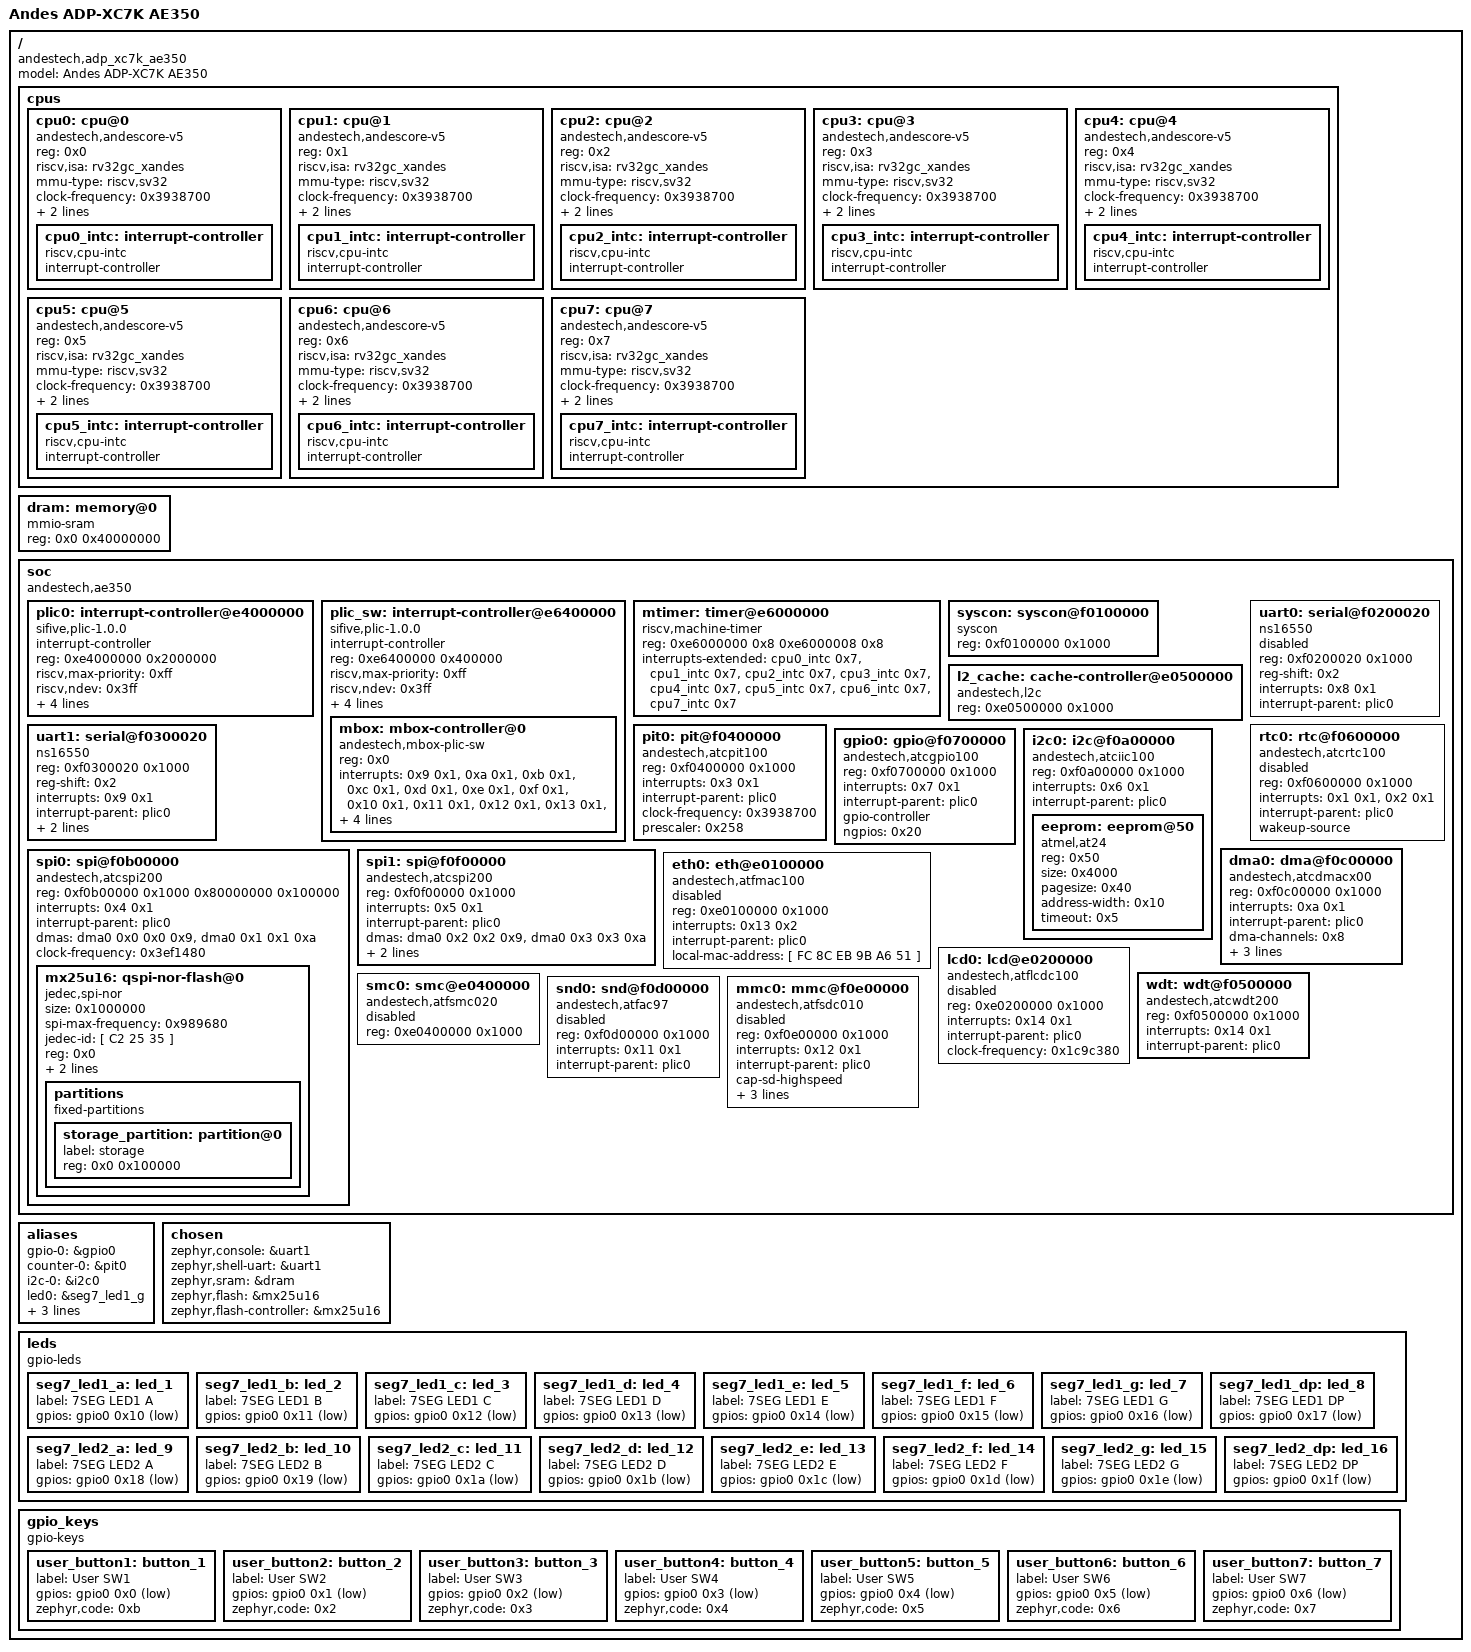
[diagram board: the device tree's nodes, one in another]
/dts-v1/;

/* node '/' defined in zephyr/dts/riscv/andes/andes_v5_ae350.dtsi:11 */
/ {
	#address-cells = < 0x1 >;                /* in zephyr/dts/riscv/andes/andes_v5_ae350.dtsi:12 */
	#size-cells = < 0x1 >;                   /* in zephyr/dts/riscv/andes/andes_v5_ae350.dtsi:13 */
	model = "Andes ADP-XC7K AE350";          /* in zephyr/boards/andestech/adp_xc7k_ae350/adp_xc7k_ae350.dts:14 */
	compatible = "andestech,adp_xc7k_ae350"; /* in zephyr/boards/andestech/adp_xc7k_ae350/adp_xc7k_ae350.dts:15 */

	/* node '/cpus' defined in zephyr/dts/riscv/andes/andes_v5_ae350.dtsi:15 */
	cpus {
		#address-cells = < 0x1 >; /* in zephyr/dts/riscv/andes/andes_v5_ae350.dtsi:16 */
		#size-cells = < 0x0 >;    /* in zephyr/dts/riscv/andes/andes_v5_ae350.dtsi:17 */

		/* node '/cpus/cpu@0' defined in zephyr/dts/riscv/andes/andes_v5_ae350.dtsi:19 */
		cpu0: cpu@0 {
			compatible = "andestech,andescore-v5",
			             "riscv";                  /* in zephyr/dts/riscv/andes/andes_v5_ae350.dtsi:20 */
			device_type = "cpu";                   /* in zephyr/dts/riscv/andes/andes_v5_ae350.dtsi:21 */
			reg = < 0x0 >;                         /* in zephyr/dts/riscv/andes/andes_v5_ae350.dtsi:22 */
			status = "okay";                       /* in zephyr/dts/riscv/andes/andes_v5_ae350.dtsi:23 */
			riscv,isa = "rv32gc_xandes";           /* in zephyr/dts/riscv/andes/andes_v5_ae350.dtsi:24 */
			mmu-type = "riscv,sv32";               /* in zephyr/dts/riscv/andes/andes_v5_ae350.dtsi:25 */
			clock-frequency = < 0x3938700 >;       /* in zephyr/dts/riscv/andes/andes_v5_ae350.dtsi:26 */
			i-cache-line-size = < 0x20 >;          /* in zephyr/dts/riscv/andes/andes_v5_ae350.dtsi:27 */
			d-cache-line-size = < 0x20 >;          /* in zephyr/dts/riscv/andes/andes_v5_ae350.dtsi:28 */

			/* node '/cpus/cpu@0/interrupt-controller' defined in zephyr/dts/riscv/andes/andes_v5_ae350.dtsi:30 */
			cpu0_intc: interrupt-controller {
				compatible = "riscv,cpu-intc"; /* in zephyr/dts/riscv/andes/andes_v5_ae350.dtsi:31 */
				#address-cells = < 0x0 >;      /* in zephyr/dts/riscv/andes/andes_v5_ae350.dtsi:32 */
				#interrupt-cells = < 0x1 >;    /* in zephyr/dts/riscv/andes/andes_v5_ae350.dtsi:33 */
				interrupt-controller;          /* in zephyr/dts/riscv/andes/andes_v5_ae350.dtsi:34 */
				phandle = < 0x1 >;             /* in zephyr/dts/riscv/andes/andes_v5_ae350.dtsi:192 */
			};
		};

		/* node '/cpus/cpu@1' defined in zephyr/dts/riscv/andes/andes_v5_ae350.dtsi:38 */
		cpu1: cpu@1 {
			compatible = "andestech,andescore-v5",
			             "riscv";                  /* in zephyr/dts/riscv/andes/andes_v5_ae350.dtsi:39 */
			device_type = "cpu";                   /* in zephyr/dts/riscv/andes/andes_v5_ae350.dtsi:40 */
			reg = < 0x1 >;                         /* in zephyr/dts/riscv/andes/andes_v5_ae350.dtsi:41 */
			status = "okay";                       /* in zephyr/dts/riscv/andes/andes_v5_ae350.dtsi:42 */
			riscv,isa = "rv32gc_xandes";           /* in zephyr/dts/riscv/andes/andes_v5_ae350.dtsi:43 */
			mmu-type = "riscv,sv32";               /* in zephyr/dts/riscv/andes/andes_v5_ae350.dtsi:44 */
			clock-frequency = < 0x3938700 >;       /* in zephyr/dts/riscv/andes/andes_v5_ae350.dtsi:45 */
			i-cache-line-size = < 0x20 >;          /* in zephyr/dts/riscv/andes/andes_v5_ae350.dtsi:46 */
			d-cache-line-size = < 0x20 >;          /* in zephyr/dts/riscv/andes/andes_v5_ae350.dtsi:47 */

			/* node '/cpus/cpu@1/interrupt-controller' defined in zephyr/dts/riscv/andes/andes_v5_ae350.dtsi:49 */
			cpu1_intc: interrupt-controller {
				compatible = "riscv,cpu-intc"; /* in zephyr/dts/riscv/andes/andes_v5_ae350.dtsi:50 */
				#address-cells = < 0x0 >;      /* in zephyr/dts/riscv/andes/andes_v5_ae350.dtsi:51 */
				#interrupt-cells = < 0x1 >;    /* in zephyr/dts/riscv/andes/andes_v5_ae350.dtsi:52 */
				interrupt-controller;          /* in zephyr/dts/riscv/andes/andes_v5_ae350.dtsi:53 */
				phandle = < 0x2 >;             /* in zephyr/dts/riscv/andes/andes_v5_ae350.dtsi:192 */
			};
		};

		/* node '/cpus/cpu@2' defined in zephyr/dts/riscv/andes/andes_v5_ae350.dtsi:57 */
		cpu2: cpu@2 {
			compatible = "andestech,andescore-v5",
			             "riscv";                  /* in zephyr/dts/riscv/andes/andes_v5_ae350.dtsi:58 */
			device_type = "cpu";                   /* in zephyr/dts/riscv/andes/andes_v5_ae350.dtsi:59 */
			reg = < 0x2 >;                         /* in zephyr/dts/riscv/andes/andes_v5_ae350.dtsi:60 */
			status = "okay";                       /* in zephyr/dts/riscv/andes/andes_v5_ae350.dtsi:61 */
			riscv,isa = "rv32gc_xandes";           /* in zephyr/dts/riscv/andes/andes_v5_ae350.dtsi:62 */
			mmu-type = "riscv,sv32";               /* in zephyr/dts/riscv/andes/andes_v5_ae350.dtsi:63 */
			clock-frequency = < 0x3938700 >;       /* in zephyr/dts/riscv/andes/andes_v5_ae350.dtsi:64 */
			i-cache-line-size = < 0x20 >;          /* in zephyr/dts/riscv/andes/andes_v5_ae350.dtsi:65 */
			d-cache-line-size = < 0x20 >;          /* in zephyr/dts/riscv/andes/andes_v5_ae350.dtsi:66 */

			/* node '/cpus/cpu@2/interrupt-controller' defined in zephyr/dts/riscv/andes/andes_v5_ae350.dtsi:68 */
			cpu2_intc: interrupt-controller {
				compatible = "riscv,cpu-intc"; /* in zephyr/dts/riscv/andes/andes_v5_ae350.dtsi:69 */
				#address-cells = < 0x0 >;      /* in zephyr/dts/riscv/andes/andes_v5_ae350.dtsi:70 */
				#interrupt-cells = < 0x1 >;    /* in zephyr/dts/riscv/andes/andes_v5_ae350.dtsi:71 */
				interrupt-controller;          /* in zephyr/dts/riscv/andes/andes_v5_ae350.dtsi:72 */
				phandle = < 0x3 >;             /* in zephyr/dts/riscv/andes/andes_v5_ae350.dtsi:192 */
			};
		};

		/* node '/cpus/cpu@3' defined in zephyr/dts/riscv/andes/andes_v5_ae350.dtsi:76 */
		cpu3: cpu@3 {
			compatible = "andestech,andescore-v5",
			             "riscv";                  /* in zephyr/dts/riscv/andes/andes_v5_ae350.dtsi:77 */
			device_type = "cpu";                   /* in zephyr/dts/riscv/andes/andes_v5_ae350.dtsi:78 */
			reg = < 0x3 >;                         /* in zephyr/dts/riscv/andes/andes_v5_ae350.dtsi:79 */
			status = "okay";                       /* in zephyr/dts/riscv/andes/andes_v5_ae350.dtsi:80 */
			riscv,isa = "rv32gc_xandes";           /* in zephyr/dts/riscv/andes/andes_v5_ae350.dtsi:81 */
			mmu-type = "riscv,sv32";               /* in zephyr/dts/riscv/andes/andes_v5_ae350.dtsi:82 */
			clock-frequency = < 0x3938700 >;       /* in zephyr/dts/riscv/andes/andes_v5_ae350.dtsi:83 */
			i-cache-line-size = < 0x20 >;          /* in zephyr/dts/riscv/andes/andes_v5_ae350.dtsi:84 */
			d-cache-line-size = < 0x20 >;          /* in zephyr/dts/riscv/andes/andes_v5_ae350.dtsi:85 */

			/* node '/cpus/cpu@3/interrupt-controller' defined in zephyr/dts/riscv/andes/andes_v5_ae350.dtsi:87 */
			cpu3_intc: interrupt-controller {
				compatible = "riscv,cpu-intc"; /* in zephyr/dts/riscv/andes/andes_v5_ae350.dtsi:88 */
				#address-cells = < 0x0 >;      /* in zephyr/dts/riscv/andes/andes_v5_ae350.dtsi:89 */
				#interrupt-cells = < 0x1 >;    /* in zephyr/dts/riscv/andes/andes_v5_ae350.dtsi:90 */
				interrupt-controller;          /* in zephyr/dts/riscv/andes/andes_v5_ae350.dtsi:91 */
				phandle = < 0x4 >;             /* in zephyr/dts/riscv/andes/andes_v5_ae350.dtsi:192 */
			};
		};

		/* node '/cpus/cpu@4' defined in zephyr/dts/riscv/andes/andes_v5_ae350.dtsi:95 */
		cpu4: cpu@4 {
			compatible = "andestech,andescore-v5",
			             "riscv";                  /* in zephyr/dts/riscv/andes/andes_v5_ae350.dtsi:96 */
			device_type = "cpu";                   /* in zephyr/dts/riscv/andes/andes_v5_ae350.dtsi:97 */
			reg = < 0x4 >;                         /* in zephyr/dts/riscv/andes/andes_v5_ae350.dtsi:98 */
			status = "okay";                       /* in zephyr/dts/riscv/andes/andes_v5_ae350.dtsi:99 */
			riscv,isa = "rv32gc_xandes";           /* in zephyr/dts/riscv/andes/andes_v5_ae350.dtsi:100 */
			mmu-type = "riscv,sv32";               /* in zephyr/dts/riscv/andes/andes_v5_ae350.dtsi:101 */
			clock-frequency = < 0x3938700 >;       /* in zephyr/dts/riscv/andes/andes_v5_ae350.dtsi:102 */
			i-cache-line-size = < 0x20 >;          /* in zephyr/dts/riscv/andes/andes_v5_ae350.dtsi:103 */
			d-cache-line-size = < 0x20 >;          /* in zephyr/dts/riscv/andes/andes_v5_ae350.dtsi:104 */

			/* node '/cpus/cpu@4/interrupt-controller' defined in zephyr/dts/riscv/andes/andes_v5_ae350.dtsi:106 */
			cpu4_intc: interrupt-controller {
				compatible = "riscv,cpu-intc"; /* in zephyr/dts/riscv/andes/andes_v5_ae350.dtsi:107 */
				#address-cells = < 0x0 >;      /* in zephyr/dts/riscv/andes/andes_v5_ae350.dtsi:108 */
				#interrupt-cells = < 0x1 >;    /* in zephyr/dts/riscv/andes/andes_v5_ae350.dtsi:109 */
				interrupt-controller;          /* in zephyr/dts/riscv/andes/andes_v5_ae350.dtsi:110 */
				phandle = < 0x5 >;             /* in zephyr/dts/riscv/andes/andes_v5_ae350.dtsi:192 */
			};
		};

		/* node '/cpus/cpu@5' defined in zephyr/dts/riscv/andes/andes_v5_ae350.dtsi:114 */
		cpu5: cpu@5 {
			compatible = "andestech,andescore-v5",
			             "riscv";                  /* in zephyr/dts/riscv/andes/andes_v5_ae350.dtsi:115 */
			device_type = "cpu";                   /* in zephyr/dts/riscv/andes/andes_v5_ae350.dtsi:116 */
			reg = < 0x5 >;                         /* in zephyr/dts/riscv/andes/andes_v5_ae350.dtsi:117 */
			status = "okay";                       /* in zephyr/dts/riscv/andes/andes_v5_ae350.dtsi:118 */
			riscv,isa = "rv32gc_xandes";           /* in zephyr/dts/riscv/andes/andes_v5_ae350.dtsi:119 */
			mmu-type = "riscv,sv32";               /* in zephyr/dts/riscv/andes/andes_v5_ae350.dtsi:120 */
			clock-frequency = < 0x3938700 >;       /* in zephyr/dts/riscv/andes/andes_v5_ae350.dtsi:121 */
			i-cache-line-size = < 0x20 >;          /* in zephyr/dts/riscv/andes/andes_v5_ae350.dtsi:122 */
			d-cache-line-size = < 0x20 >;          /* in zephyr/dts/riscv/andes/andes_v5_ae350.dtsi:123 */

			/* node '/cpus/cpu@5/interrupt-controller' defined in zephyr/dts/riscv/andes/andes_v5_ae350.dtsi:125 */
			cpu5_intc: interrupt-controller {
				compatible = "riscv,cpu-intc"; /* in zephyr/dts/riscv/andes/andes_v5_ae350.dtsi:126 */
				#address-cells = < 0x0 >;      /* in zephyr/dts/riscv/andes/andes_v5_ae350.dtsi:127 */
				#interrupt-cells = < 0x1 >;    /* in zephyr/dts/riscv/andes/andes_v5_ae350.dtsi:128 */
				interrupt-controller;          /* in zephyr/dts/riscv/andes/andes_v5_ae350.dtsi:129 */
				phandle = < 0x6 >;             /* in zephyr/dts/riscv/andes/andes_v5_ae350.dtsi:192 */
			};
		};

		/* node '/cpus/cpu@6' defined in zephyr/dts/riscv/andes/andes_v5_ae350.dtsi:133 */
		cpu6: cpu@6 {
			compatible = "andestech,andescore-v5",
			             "riscv";                  /* in zephyr/dts/riscv/andes/andes_v5_ae350.dtsi:134 */
			device_type = "cpu";                   /* in zephyr/dts/riscv/andes/andes_v5_ae350.dtsi:135 */
			reg = < 0x6 >;                         /* in zephyr/dts/riscv/andes/andes_v5_ae350.dtsi:136 */
			status = "okay";                       /* in zephyr/dts/riscv/andes/andes_v5_ae350.dtsi:137 */
			riscv,isa = "rv32gc_xandes";           /* in zephyr/dts/riscv/andes/andes_v5_ae350.dtsi:138 */
			mmu-type = "riscv,sv32";               /* in zephyr/dts/riscv/andes/andes_v5_ae350.dtsi:139 */
			clock-frequency = < 0x3938700 >;       /* in zephyr/dts/riscv/andes/andes_v5_ae350.dtsi:140 */
			i-cache-line-size = < 0x20 >;          /* in zephyr/dts/riscv/andes/andes_v5_ae350.dtsi:141 */
			d-cache-line-size = < 0x20 >;          /* in zephyr/dts/riscv/andes/andes_v5_ae350.dtsi:142 */

			/* node '/cpus/cpu@6/interrupt-controller' defined in zephyr/dts/riscv/andes/andes_v5_ae350.dtsi:144 */
			cpu6_intc: interrupt-controller {
				compatible = "riscv,cpu-intc"; /* in zephyr/dts/riscv/andes/andes_v5_ae350.dtsi:145 */
				#address-cells = < 0x0 >;      /* in zephyr/dts/riscv/andes/andes_v5_ae350.dtsi:146 */
				#interrupt-cells = < 0x1 >;    /* in zephyr/dts/riscv/andes/andes_v5_ae350.dtsi:147 */
				interrupt-controller;          /* in zephyr/dts/riscv/andes/andes_v5_ae350.dtsi:148 */
				phandle = < 0x7 >;             /* in zephyr/dts/riscv/andes/andes_v5_ae350.dtsi:192 */
			};
		};

		/* node '/cpus/cpu@7' defined in zephyr/dts/riscv/andes/andes_v5_ae350.dtsi:152 */
		cpu7: cpu@7 {
			compatible = "andestech,andescore-v5",
			             "riscv";                  /* in zephyr/dts/riscv/andes/andes_v5_ae350.dtsi:153 */
			device_type = "cpu";                   /* in zephyr/dts/riscv/andes/andes_v5_ae350.dtsi:154 */
			reg = < 0x7 >;                         /* in zephyr/dts/riscv/andes/andes_v5_ae350.dtsi:155 */
			status = "okay";                       /* in zephyr/dts/riscv/andes/andes_v5_ae350.dtsi:156 */
			riscv,isa = "rv32gc_xandes";           /* in zephyr/dts/riscv/andes/andes_v5_ae350.dtsi:157 */
			mmu-type = "riscv,sv32";               /* in zephyr/dts/riscv/andes/andes_v5_ae350.dtsi:158 */
			clock-frequency = < 0x3938700 >;       /* in zephyr/dts/riscv/andes/andes_v5_ae350.dtsi:159 */
			i-cache-line-size = < 0x20 >;          /* in zephyr/dts/riscv/andes/andes_v5_ae350.dtsi:160 */
			d-cache-line-size = < 0x20 >;          /* in zephyr/dts/riscv/andes/andes_v5_ae350.dtsi:161 */

			/* node '/cpus/cpu@7/interrupt-controller' defined in zephyr/dts/riscv/andes/andes_v5_ae350.dtsi:163 */
			cpu7_intc: interrupt-controller {
				compatible = "riscv,cpu-intc"; /* in zephyr/dts/riscv/andes/andes_v5_ae350.dtsi:164 */
				#address-cells = < 0x0 >;      /* in zephyr/dts/riscv/andes/andes_v5_ae350.dtsi:165 */
				#interrupt-cells = < 0x1 >;    /* in zephyr/dts/riscv/andes/andes_v5_ae350.dtsi:166 */
				interrupt-controller;          /* in zephyr/dts/riscv/andes/andes_v5_ae350.dtsi:167 */
				phandle = < 0x8 >;             /* in zephyr/dts/riscv/andes/andes_v5_ae350.dtsi:192 */
			};
		};
	};

	/* node '/memory@0' defined in zephyr/dts/riscv/andes/andes_v5_ae350.dtsi:172 */
	dram: memory@0 {
		device_type = "memory";   /* in zephyr/dts/riscv/andes/andes_v5_ae350.dtsi:173 */
		compatible = "mmio-sram"; /* in zephyr/dts/riscv/andes/andes_v5_ae350.dtsi:174 */
		reg = < 0x0 0x40000000 >; /* in zephyr/dts/riscv/andes/andes_v5_ae350.dtsi:175 */
	};

	/* node '/soc' defined in zephyr/dts/riscv/andes/andes_v5_ae350.dtsi:178 */
	soc {
		#address-cells = < 0x1 >;       /* in zephyr/dts/riscv/andes/andes_v5_ae350.dtsi:179 */
		#size-cells = < 0x1 >;          /* in zephyr/dts/riscv/andes/andes_v5_ae350.dtsi:180 */
		compatible = "andestech,ae350"; /* in zephyr/dts/riscv/andes/andes_v5_ae350.dtsi:181 */
		ranges;                         /* in zephyr/dts/riscv/andes/andes_v5_ae350.dtsi:182 */

		/* node '/soc/interrupt-controller@e4000000' defined in zephyr/dts/riscv/andes/andes_v5_ae350.dtsi:184 */
		plic0: interrupt-controller@e4000000 {
			compatible = "sifive,plic-1.0.0",
			             "andestech,nceplic100";                                                                          /* in zephyr/dts/riscv/andes/andes_v5_ae350.dtsi:185 */
			#address-cells = < 0x1 >;                                                                                     /* in zephyr/dts/riscv/andes/andes_v5_ae350.dtsi:186 */
			#interrupt-cells = < 0x2 >;                                                                                   /* in zephyr/dts/riscv/andes/andes_v5_ae350.dtsi:187 */
			interrupt-controller;                                                                                         /* in zephyr/dts/riscv/andes/andes_v5_ae350.dtsi:188 */
			reg = < 0xe4000000 0x2000000 >;                                                                               /* in zephyr/dts/riscv/andes/andes_v5_ae350.dtsi:189 */
			riscv,max-priority = < 0xff >;                                                                                /* in zephyr/dts/riscv/andes/andes_v5_ae350.dtsi:190 */
			riscv,ndev = < 0x3ff >;                                                                                       /* in zephyr/dts/riscv/andes/andes_v5_ae350.dtsi:191 */
			interrupts-extended = < &cpu0_intc 0xb &cpu1_intc 0xb &cpu2_intc 0xb &cpu3_intc 0xb &cpu4_intc 0xb &cpu5_intc
			                        0xb &cpu6_intc 0xb &cpu7_intc 0xb >;                                                  /* in zephyr/dts/riscv/andes/andes_v5_ae350.dtsi:192 */
			phandle = < 0xa >;                                                                                            /* in zephyr/dts/riscv/andes/andes_v5_ae350.dtsi:261 */
		};

		/* node '/soc/interrupt-controller@e6400000' defined in zephyr/dts/riscv/andes/andes_v5_ae350.dtsi:198 */
		plic_sw: interrupt-controller@e6400000 {
			compatible = "sifive,plic-1.0.0",
			             "andestech,nceplic100";                                                                          /* in zephyr/dts/riscv/andes/andes_v5_ae350.dtsi:199 */
			#address-cells = < 0x1 >;                                                                                     /* in zephyr/dts/riscv/andes/andes_v5_ae350.dtsi:200 */
			#interrupt-cells = < 0x2 >;                                                                                   /* in zephyr/dts/riscv/andes/andes_v5_ae350.dtsi:201 */
			interrupt-controller;                                                                                         /* in zephyr/dts/riscv/andes/andes_v5_ae350.dtsi:202 */
			reg = < 0xe6400000 0x400000 >;                                                                                /* in zephyr/dts/riscv/andes/andes_v5_ae350.dtsi:203 */
			riscv,max-priority = < 0xff >;                                                                                /* in zephyr/dts/riscv/andes/andes_v5_ae350.dtsi:204 */
			riscv,ndev = < 0x3ff >;                                                                                       /* in zephyr/dts/riscv/andes/andes_v5_ae350.dtsi:205 */
			interrupts-extended = < &cpu0_intc 0x3 &cpu1_intc 0x3 &cpu2_intc 0x3 &cpu3_intc 0x3 &cpu4_intc 0x3 &cpu5_intc
			                        0x3 &cpu6_intc 0x3 &cpu7_intc 0x3 >;                                                  /* in zephyr/dts/riscv/andes/andes_v5_ae350.dtsi:206 */
			#size-cells = < 0x0 >;                                                                                        /* in zephyr/dts/riscv/andes/andes_v5_ae350.dtsi:211 */
			phandle = < 0x9 >;                                                                                            /* in zephyr/dts/riscv/andes/andes_v5_ae350.dtsi:229 */

			/* node '/soc/interrupt-controller@e6400000/mbox-controller@0' defined in zephyr/dts/riscv/andes/andes_v5_ae350.dtsi:213 */
			mbox: mbox-controller@0 {
				compatible = "andestech,mbox-plic-sw"; /* in zephyr/dts/riscv/andes/andes_v5_ae350.dtsi:214 */
				#mbox-cells = < 0x1 >;                 /* in zephyr/dts/riscv/andes/andes_v5_ae350.dtsi:215 */
				reg = < 0x0 >;                         /* in zephyr/dts/riscv/andes/andes_v5_ae350.dtsi:216 */
				interrupts = < 0x9 0x1 >,
				             < 0xa 0x1 >,
				             < 0xb 0x1 >,
				             < 0xc 0x1 >,
				             < 0xd 0x1 >,
				             < 0xe 0x1 >,
				             < 0xf 0x1 >,
				             < 0x10 0x1 >,
				             < 0x11 0x1 >,
				             < 0x12 0x1 >,
				             < 0x13 0x1 >,
				             < 0x14 0x1 >,
				             < 0x15 0x1 >,
				             < 0x16 0x1 >,
				             < 0x17 0x1 >,
				             < 0x18 0x1 >,
				             < 0x19 0x1 >,
				             < 0x1a 0x1 >,
				             < 0x1b 0x1 >,
				             < 0x1c 0x1 >,
				             < 0x1d 0x1 >,
				             < 0x1e 0x1 >,
				             < 0x1f 0x1 >;             /* in zephyr/dts/riscv/andes/andes_v5_ae350.dtsi:217 */
				interrupt-names = "mbox_9",
				                  "mbox_10",
				                  "mbox_11",
				                  "mbox_12",
				                  "mbox_13",
				                  "mbox_14",
				                  "mbox_15",
				                  "mbox_16",
				                  "mbox_17",
				                  "mbox_18",
				                  "mbox_19",
				                  "mbox_20",
				                  "mbox_21",
				                  "mbox_22",
				                  "mbox_23",
				                  "mbox_24",
				                  "mbox_25",
				                  "mbox_26",
				                  "mbox_27",
				                  "mbox_28",
				                  "mbox_29",
				                  "mbox_30",
				                  "mbox_31";           /* in zephyr/dts/riscv/andes/andes_v5_ae350.dtsi:223 */
				interrupt-parent = < &plic_sw >;       /* in zephyr/dts/riscv/andes/andes_v5_ae350.dtsi:229 */
				status = "okay";                       /* in zephyr/boards/andestech/adp_xc7k_ae350/adp_xc7k_ae350.dts:19 */
			};
		};

		/* node '/soc/timer@e6000000' defined in zephyr/dts/riscv/andes/andes_v5_ae350.dtsi:234 */
		mtimer: timer@e6000000 {
			compatible = "riscv,machine-timer";                                                                           /* in zephyr/dts/riscv/andes/andes_v5_ae350.dtsi:235 */
			reg = < 0xe6000000 0x8 0xe6000008 0x8 >;                                                                      /* in zephyr/dts/riscv/andes/andes_v5_ae350.dtsi:236 */
			reg-names = "mtime",
			            "mtimecmp";                                                                                       /* in zephyr/dts/riscv/andes/andes_v5_ae350.dtsi:237 */
			interrupts-extended = < &cpu0_intc 0x7 &cpu1_intc 0x7 &cpu2_intc 0x7 &cpu3_intc 0x7 &cpu4_intc 0x7 &cpu5_intc
			                        0x7 &cpu6_intc 0x7 &cpu7_intc 0x7 >;                                                  /* in zephyr/dts/riscv/andes/andes_v5_ae350.dtsi:238 */
		};

		/* node '/soc/syscon@f0100000' defined in zephyr/dts/riscv/andes/andes_v5_ae350.dtsi:244 */
		syscon: syscon@f0100000 {
			compatible = "syscon",
			             "andestech,atcsmu100"; /* in zephyr/dts/riscv/andes/andes_v5_ae350.dtsi:245 */
			reg = < 0xf0100000 0x1000 >;        /* in zephyr/dts/riscv/andes/andes_v5_ae350.dtsi:246 */
			status = "okay";                    /* in zephyr/boards/andestech/adp_xc7k_ae350/adp_xc7k_ae350_common.dtsi:164 */
		};

		/* node '/soc/cache-controller@e0500000' defined in zephyr/dts/riscv/andes/andes_v5_ae350.dtsi:250 */
		l2_cache: cache-controller@e0500000 {
			compatible = "andestech,l2c"; /* in zephyr/dts/riscv/andes/andes_v5_ae350.dtsi:251 */
			reg = < 0xe0500000 0x1000 >;  /* in zephyr/dts/riscv/andes/andes_v5_ae350.dtsi:252 */
			status = "okay";              /* in zephyr/boards/andestech/adp_xc7k_ae350/adp_xc7k_ae350_common.dtsi:160 */
		};

		/* node '/soc/serial@f0200020' defined in zephyr/dts/riscv/andes/andes_v5_ae350.dtsi:256 */
		uart0: serial@f0200020 {
			compatible = "ns16550";        /* in zephyr/dts/riscv/andes/andes_v5_ae350.dtsi:257 */
			reg = < 0xf0200020 0x1000 >;   /* in zephyr/dts/riscv/andes/andes_v5_ae350.dtsi:258 */
			reg-shift = < 0x2 >;           /* in zephyr/dts/riscv/andes/andes_v5_ae350.dtsi:259 */
			interrupts = < 0x8 0x1 >;      /* in zephyr/dts/riscv/andes/andes_v5_ae350.dtsi:260 */
			interrupt-parent = < &plic0 >; /* in zephyr/dts/riscv/andes/andes_v5_ae350.dtsi:261 */
			status = "disabled";           /* in zephyr/dts/riscv/andes/andes_v5_ae350.dtsi:262 */
		};

		/* node '/soc/serial@f0300020' defined in zephyr/dts/riscv/andes/andes_v5_ae350.dtsi:265 */
		uart1: serial@f0300020 {
			compatible = "ns16550";          /* in zephyr/dts/riscv/andes/andes_v5_ae350.dtsi:266 */
			reg = < 0xf0300020 0x1000 >;     /* in zephyr/dts/riscv/andes/andes_v5_ae350.dtsi:267 */
			reg-shift = < 0x2 >;             /* in zephyr/dts/riscv/andes/andes_v5_ae350.dtsi:268 */
			interrupts = < 0x9 0x1 >;        /* in zephyr/dts/riscv/andes/andes_v5_ae350.dtsi:269 */
			interrupt-parent = < &plic0 >;   /* in zephyr/dts/riscv/andes/andes_v5_ae350.dtsi:270 */
			status = "okay";                 /* in zephyr/boards/andestech/adp_xc7k_ae350/adp_xc7k_ae350_common.dtsi:168 */
			clock-frequency = < 0x1312d00 >; /* in zephyr/boards/andestech/adp_xc7k_ae350/adp_xc7k_ae350_common.dtsi:169 */
			current-speed = < 0x1c200 >;     /* in zephyr/boards/andestech/adp_xc7k_ae350/adp_xc7k_ae350_common.dtsi:170 */
		};

		/* node '/soc/pit@f0400000' defined in zephyr/dts/riscv/andes/andes_v5_ae350.dtsi:274 */
		pit0: pit@f0400000 {
			compatible = "andestech,atcpit100"; /* in zephyr/dts/riscv/andes/andes_v5_ae350.dtsi:275 */
			reg = < 0xf0400000 0x1000 >;        /* in zephyr/dts/riscv/andes/andes_v5_ae350.dtsi:276 */
			interrupts = < 0x3 0x1 >;           /* in zephyr/dts/riscv/andes/andes_v5_ae350.dtsi:277 */
			interrupt-parent = < &plic0 >;      /* in zephyr/dts/riscv/andes/andes_v5_ae350.dtsi:278 */
			clock-frequency = < 0x3938700 >;    /* in zephyr/dts/riscv/andes/andes_v5_ae350.dtsi:279 */
			prescaler = < 0x258 >;              /* in zephyr/dts/riscv/andes/andes_v5_ae350.dtsi:280 */
			status = "okay";                    /* in zephyr/boards/andestech/adp_xc7k_ae350/adp_xc7k_ae350_common.dtsi:178 */
		};

		/* node '/soc/rtc@f0600000' defined in zephyr/dts/riscv/andes/andes_v5_ae350.dtsi:284 */
		rtc0: rtc@f0600000 {
			compatible = "andestech,atcrtc100"; /* in zephyr/dts/riscv/andes/andes_v5_ae350.dtsi:285 */
			reg = < 0xf0600000 0x1000 >;        /* in zephyr/dts/riscv/andes/andes_v5_ae350.dtsi:286 */
			interrupts = < 0x1 0x1 >,
			             < 0x2 0x1 >;           /* in zephyr/dts/riscv/andes/andes_v5_ae350.dtsi:287 */
			interrupt-parent = < &plic0 >;      /* in zephyr/dts/riscv/andes/andes_v5_ae350.dtsi:288 */
			wakeup-source;                      /* in zephyr/dts/riscv/andes/andes_v5_ae350.dtsi:289 */
			status = "disabled";                /* in zephyr/dts/riscv/andes/andes_v5_ae350.dtsi:290 */
		};

		/* node '/soc/gpio@f0700000' defined in zephyr/dts/riscv/andes/andes_v5_ae350.dtsi:293 */
		gpio0: gpio@f0700000 {
			compatible = "andestech,atcgpio100"; /* in zephyr/dts/riscv/andes/andes_v5_ae350.dtsi:294 */
			reg = < 0xf0700000 0x1000 >;         /* in zephyr/dts/riscv/andes/andes_v5_ae350.dtsi:295 */
			interrupts = < 0x7 0x1 >;            /* in zephyr/dts/riscv/andes/andes_v5_ae350.dtsi:296 */
			interrupt-parent = < &plic0 >;       /* in zephyr/dts/riscv/andes/andes_v5_ae350.dtsi:297 */
			gpio-controller;                     /* in zephyr/dts/riscv/andes/andes_v5_ae350.dtsi:298 */
			ngpios = < 0x20 >;                   /* in zephyr/dts/riscv/andes/andes_v5_ae350.dtsi:299 */
			#gpio-cells = < 0x2 >;               /* in zephyr/dts/riscv/andes/andes_v5_ae350.dtsi:300 */
			status = "okay";                     /* in zephyr/boards/andestech/adp_xc7k_ae350/adp_xc7k_ae350_common.dtsi:174 */
			phandle = < 0xc >;                   /* in zephyr/boards/andestech/adp_xc7k_ae350/adp_xc7k_ae350_common.dtsi:224 */
		};

		/* node '/soc/i2c@f0a00000' defined in zephyr/dts/riscv/andes/andes_v5_ae350.dtsi:304 */
		i2c0: i2c@f0a00000 {
			compatible = "andestech,atciic100"; /* in zephyr/dts/riscv/andes/andes_v5_ae350.dtsi:305 */
			reg = < 0xf0a00000 0x1000 >;        /* in zephyr/dts/riscv/andes/andes_v5_ae350.dtsi:306 */
			interrupts = < 0x6 0x1 >;           /* in zephyr/dts/riscv/andes/andes_v5_ae350.dtsi:307 */
			interrupt-parent = < &plic0 >;      /* in zephyr/dts/riscv/andes/andes_v5_ae350.dtsi:308 */
			#address-cells = < 0x1 >;           /* in zephyr/dts/riscv/andes/andes_v5_ae350.dtsi:309 */
			#size-cells = < 0x0 >;              /* in zephyr/dts/riscv/andes/andes_v5_ae350.dtsi:310 */
			status = "okay";                    /* in zephyr/boards/andestech/adp_xc7k_ae350/adp_xc7k_ae350_common.dtsi:209 */

			/* node '/soc/i2c@f0a00000/eeprom@50' defined in zephyr/boards/andestech/adp_xc7k_ae350/adp_xc7k_ae350_common.dtsi:211 */
			eeprom: eeprom@50 {
				compatible = "atmel,at24"; /* in zephyr/boards/andestech/adp_xc7k_ae350/adp_xc7k_ae350_common.dtsi:212 */
				reg = < 0x50 >;            /* in zephyr/boards/andestech/adp_xc7k_ae350/adp_xc7k_ae350_common.dtsi:213 */
				status = "okay";           /* in zephyr/boards/andestech/adp_xc7k_ae350/adp_xc7k_ae350_common.dtsi:214 */
				size = < 0x4000 >;         /* in zephyr/boards/andestech/adp_xc7k_ae350/adp_xc7k_ae350_common.dtsi:215 */
				pagesize = < 0x40 >;       /* in zephyr/boards/andestech/adp_xc7k_ae350/adp_xc7k_ae350_common.dtsi:216 */
				address-width = < 0x10 >;  /* in zephyr/boards/andestech/adp_xc7k_ae350/adp_xc7k_ae350_common.dtsi:217 */
				timeout = < 0x5 >;         /* in zephyr/boards/andestech/adp_xc7k_ae350/adp_xc7k_ae350_common.dtsi:218 */
			};
		};

		/* node '/soc/spi@f0b00000' defined in zephyr/dts/riscv/andes/andes_v5_ae350.dtsi:314 */
		spi0: spi@f0b00000 {
			compatible = "andestech,atcspi200";              /* in zephyr/dts/riscv/andes/andes_v5_ae350.dtsi:315 */
			reg = < 0xf0b00000 0x1000 0x80000000 0x100000 >; /* in zephyr/dts/riscv/andes/andes_v5_ae350.dtsi:316 */
			reg-names = "control",
			            "mem";                               /* in zephyr/dts/riscv/andes/andes_v5_ae350.dtsi:318 */
			interrupts = < 0x4 0x1 >;                        /* in zephyr/dts/riscv/andes/andes_v5_ae350.dtsi:319 */
			interrupt-parent = < &plic0 >;                   /* in zephyr/dts/riscv/andes/andes_v5_ae350.dtsi:320 */
			dmas = < &dma0 0x0 0x0 0x9 >,
			       < &dma0 0x1 0x1 0xa >;                    /* in zephyr/dts/riscv/andes/andes_v5_ae350.dtsi:321 */
			dma-names = "tx",
			            "rx";                                /* in zephyr/dts/riscv/andes/andes_v5_ae350.dtsi:323 */
			#address-cells = < 0x1 >;                        /* in zephyr/dts/riscv/andes/andes_v5_ae350.dtsi:324 */
			#size-cells = < 0x0 >;                           /* in zephyr/dts/riscv/andes/andes_v5_ae350.dtsi:325 */
			clock-frequency = < 0x3ef1480 >;                 /* in zephyr/dts/riscv/andes/andes_v5_ae350.dtsi:326 */
			status = "okay";                                 /* in zephyr/boards/andestech/adp_xc7k_ae350/adp_xc7k_ae350_common.dtsi:182 */

			/* node '/soc/spi@f0b00000/qspi-nor-flash@0' defined in zephyr/boards/andestech/adp_xc7k_ae350/adp_xc7k_ae350_common.dtsi:184 */
			mx25u16: qspi-nor-flash@0 {
				compatible = "jedec,spi-nor",
				             "andestech,qspi-nor";                                                            /* in zephyr/boards/andestech/adp_xc7k_ae350/adp_xc7k_ae350_common.dtsi:185 */
				size = < 0x1000000 >;                                                                         /* in zephyr/boards/andestech/adp_xc7k_ae350/adp_xc7k_ae350_common.dtsi:186 */
				spi-max-frequency = < 0x989680 >;                                                             /* in zephyr/boards/andestech/adp_xc7k_ae350/adp_xc7k_ae350_common.dtsi:187 */
				jedec-id = [ C2 25 35 ];                                                                      /* in zephyr/boards/andestech/adp_xc7k_ae350/adp_xc7k_ae350_common.dtsi:188 */
				status = "okay";                                                                              /* in zephyr/boards/andestech/adp_xc7k_ae350/adp_xc7k_ae350_common.dtsi:189 */
				reg = < 0x0 >;                                                                                /* in zephyr/boards/andestech/adp_xc7k_ae350/adp_xc7k_ae350_common.dtsi:190 */
				sfdp-bfp = [ E5 20 F1 FF FF FF FF 00 44 EB 08 6B 08 3B 04 BB FE FF FF FF FF FF 00 FF FF FF 44
				             EB 0C 20 0F 52 10 D8 00 FF ];                                                    /* in zephyr/boards/andestech/adp_xc7k_ae350/adp_xc7k_ae350_common.dtsi:191 */

				/* node '/soc/spi@f0b00000/qspi-nor-flash@0/partitions' defined in zephyr/boards/andestech/adp_xc7k_ae350/adp_xc7k_ae350_common.dtsi:195 */
				partitions {
					compatible = "fixed-partitions"; /* in zephyr/boards/andestech/adp_xc7k_ae350/adp_xc7k_ae350_common.dtsi:196 */
					#address-cells = < 0x1 >;        /* in zephyr/boards/andestech/adp_xc7k_ae350/adp_xc7k_ae350_common.dtsi:197 */
					#size-cells = < 0x1 >;           /* in zephyr/boards/andestech/adp_xc7k_ae350/adp_xc7k_ae350_common.dtsi:198 */

					/* node '/soc/spi@f0b00000/qspi-nor-flash@0/partitions/partition@0' defined in zephyr/boards/andestech/adp_xc7k_ae350/adp_xc7k_ae350_common.dtsi:200 */
					storage_partition: partition@0 {
						label = "storage";      /* in zephyr/boards/andestech/adp_xc7k_ae350/adp_xc7k_ae350_common.dtsi:201 */
						reg = < 0x0 0x100000 >; /* in zephyr/boards/andestech/adp_xc7k_ae350/adp_xc7k_ae350_common.dtsi:202 */
					};
				};
			};
		};

		/* node '/soc/spi@f0f00000' defined in zephyr/dts/riscv/andes/andes_v5_ae350.dtsi:330 */
		spi1: spi@f0f00000 {
			compatible = "andestech,atcspi200"; /* in zephyr/dts/riscv/andes/andes_v5_ae350.dtsi:331 */
			reg = < 0xf0f00000 0x1000 >;        /* in zephyr/dts/riscv/andes/andes_v5_ae350.dtsi:332 */
			reg-names = "control";              /* in zephyr/dts/riscv/andes/andes_v5_ae350.dtsi:333 */
			interrupts = < 0x5 0x1 >;           /* in zephyr/dts/riscv/andes/andes_v5_ae350.dtsi:334 */
			interrupt-parent = < &plic0 >;      /* in zephyr/dts/riscv/andes/andes_v5_ae350.dtsi:335 */
			dmas = < &dma0 0x2 0x2 0x9 >,
			       < &dma0 0x3 0x3 0xa >;       /* in zephyr/dts/riscv/andes/andes_v5_ae350.dtsi:336 */
			dma-names = "tx",
			            "rx";                   /* in zephyr/dts/riscv/andes/andes_v5_ae350.dtsi:338 */
			#address-cells = < 0x1 >;           /* in zephyr/dts/riscv/andes/andes_v5_ae350.dtsi:339 */
			#size-cells = < 0x0 >;              /* in zephyr/dts/riscv/andes/andes_v5_ae350.dtsi:340 */
			clock-frequency = < 0x3ef1480 >;    /* in zephyr/dts/riscv/andes/andes_v5_ae350.dtsi:341 */
			status = "okay";                    /* in zephyr/boards/andestech/adp_xc7k_ae350/adp_xc7k_ae350_common.dtsi:223 */
			cs-gpios = < &gpio0 0x7 0x1 >;      /* in zephyr/boards/andestech/adp_xc7k_ae350/adp_xc7k_ae350_common.dtsi:224 */
		};

		/* node '/soc/dma@f0c00000' defined in zephyr/dts/riscv/andes/andes_v5_ae350.dtsi:345 */
		dma0: dma@f0c00000 {
			compatible = "andestech,atcdmacx00"; /* in zephyr/dts/riscv/andes/andes_v5_ae350.dtsi:346 */
			reg = < 0xf0c00000 0x1000 >;         /* in zephyr/dts/riscv/andes/andes_v5_ae350.dtsi:347 */
			interrupts = < 0xa 0x1 >;            /* in zephyr/dts/riscv/andes/andes_v5_ae350.dtsi:348 */
			interrupt-parent = < &plic0 >;       /* in zephyr/dts/riscv/andes/andes_v5_ae350.dtsi:349 */
			dma-channels = < 0x8 >;              /* in zephyr/dts/riscv/andes/andes_v5_ae350.dtsi:350 */
			dma-requests = < 0x10 >;             /* in zephyr/dts/riscv/andes/andes_v5_ae350.dtsi:351 */
			chain-transfer = < 0x1 >;            /* in zephyr/dts/riscv/andes/andes_v5_ae350.dtsi:352 */
			max-data-width = < 0x4 >;            /* in zephyr/dts/riscv/andes/andes_v5_ae350.dtsi:353 */
			#dma-cells = < 0x3 >;                /* in zephyr/dts/riscv/andes/andes_v5_ae350.dtsi:354 */
			status = "okay";                     /* in zephyr/boards/andestech/adp_xc7k_ae350/adp_xc7k_ae350_common.dtsi:232 */
			phandle = < 0xb >;                   /* in zephyr/dts/riscv/andes/andes_v5_ae350.dtsi:321 */
		};

		/* node '/soc/eth@e0100000' defined in zephyr/dts/riscv/andes/andes_v5_ae350.dtsi:358 */
		eth0: eth@e0100000 {
			compatible = "andestech,atfmac100";        /* in zephyr/dts/riscv/andes/andes_v5_ae350.dtsi:359 */
			reg = < 0xe0100000 0x1000 >;               /* in zephyr/dts/riscv/andes/andes_v5_ae350.dtsi:360 */
			interrupts = < 0x13 0x2 >;                 /* in zephyr/dts/riscv/andes/andes_v5_ae350.dtsi:361 */
			interrupt-parent = < &plic0 >;             /* in zephyr/dts/riscv/andes/andes_v5_ae350.dtsi:362 */
			local-mac-address = [ FC 8C EB 9B A6 51 ]; /* in zephyr/dts/riscv/andes/andes_v5_ae350.dtsi:363 */
			status = "disabled";                       /* in zephyr/dts/riscv/andes/andes_v5_ae350.dtsi:364 */
		};

		/* node '/soc/lcd@e0200000' defined in zephyr/dts/riscv/andes/andes_v5_ae350.dtsi:367 */
		lcd0: lcd@e0200000 {
			compatible = "andestech,atflcdc100"; /* in zephyr/dts/riscv/andes/andes_v5_ae350.dtsi:368 */
			reg = < 0xe0200000 0x1000 >;         /* in zephyr/dts/riscv/andes/andes_v5_ae350.dtsi:369 */
			interrupts = < 0x14 0x1 >;           /* in zephyr/dts/riscv/andes/andes_v5_ae350.dtsi:370 */
			interrupt-parent = < &plic0 >;       /* in zephyr/dts/riscv/andes/andes_v5_ae350.dtsi:371 */
			clock-frequency = < 0x1c9c380 >;     /* in zephyr/dts/riscv/andes/andes_v5_ae350.dtsi:372 */
			status = "disabled";                 /* in zephyr/dts/riscv/andes/andes_v5_ae350.dtsi:373 */
		};

		/* node '/soc/wdt@f0500000' defined in zephyr/dts/riscv/andes/andes_v5_ae350.dtsi:376 */
		wdt: wdt@f0500000 {
			compatible = "andestech,atcwdt200"; /* in zephyr/dts/riscv/andes/andes_v5_ae350.dtsi:377 */
			reg = < 0xf0500000 0x1000 >;        /* in zephyr/dts/riscv/andes/andes_v5_ae350.dtsi:378 */
			interrupts = < 0x14 0x1 >;          /* in zephyr/dts/riscv/andes/andes_v5_ae350.dtsi:379 */
			interrupt-parent = < &plic0 >;      /* in zephyr/dts/riscv/andes/andes_v5_ae350.dtsi:380 */
			status = "okay";                    /* in zephyr/boards/andestech/adp_xc7k_ae350/adp_xc7k_ae350_common.dtsi:228 */
		};

		/* node '/soc/smc@e0400000' defined in zephyr/dts/riscv/andes/andes_v5_ae350.dtsi:384 */
		smc0: smc@e0400000 {
			compatible = "andestech,atfsmc020"; /* in zephyr/dts/riscv/andes/andes_v5_ae350.dtsi:385 */
			reg = < 0xe0400000 0x1000 >;        /* in zephyr/dts/riscv/andes/andes_v5_ae350.dtsi:386 */
			status = "disabled";                /* in zephyr/dts/riscv/andes/andes_v5_ae350.dtsi:387 */
		};

		/* node '/soc/snd@f0d00000' defined in zephyr/dts/riscv/andes/andes_v5_ae350.dtsi:390 */
		snd0: snd@f0d00000 {
			compatible = "andestech,atfac97"; /* in zephyr/dts/riscv/andes/andes_v5_ae350.dtsi:391 */
			reg = < 0xf0d00000 0x1000 >;      /* in zephyr/dts/riscv/andes/andes_v5_ae350.dtsi:392 */
			interrupts = < 0x11 0x1 >;        /* in zephyr/dts/riscv/andes/andes_v5_ae350.dtsi:393 */
			interrupt-parent = < &plic0 >;    /* in zephyr/dts/riscv/andes/andes_v5_ae350.dtsi:394 */
			status = "disabled";              /* in zephyr/dts/riscv/andes/andes_v5_ae350.dtsi:395 */
		};

		/* node '/soc/mmc@f0e00000' defined in zephyr/dts/riscv/andes/andes_v5_ae350.dtsi:398 */
		mmc0: mmc@f0e00000 {
			compatible = "andestech,atfsdc010";         /* in zephyr/dts/riscv/andes/andes_v5_ae350.dtsi:399 */
			reg = < 0xf0e00000 0x1000 >;                /* in zephyr/dts/riscv/andes/andes_v5_ae350.dtsi:400 */
			interrupts = < 0x12 0x1 >;                  /* in zephyr/dts/riscv/andes/andes_v5_ae350.dtsi:401 */
			interrupt-parent = < &plic0 >;              /* in zephyr/dts/riscv/andes/andes_v5_ae350.dtsi:402 */
			cap-sd-highspeed;                           /* in zephyr/dts/riscv/andes/andes_v5_ae350.dtsi:403 */
			max-frequency = < 0x5f5e100 >;              /* in zephyr/dts/riscv/andes/andes_v5_ae350.dtsi:404 */
			clock-freq-min-max = < 0x61a80 0x5f5e100 >; /* in zephyr/dts/riscv/andes/andes_v5_ae350.dtsi:405 */
			fifo-depth = < 0x10 >;                      /* in zephyr/dts/riscv/andes/andes_v5_ae350.dtsi:406 */
			status = "disabled";                        /* in zephyr/dts/riscv/andes/andes_v5_ae350.dtsi:407 */
		};
	};

	/* node '/aliases' defined in zephyr/boards/andestech/adp_xc7k_ae350/adp_xc7k_ae350_common.dtsi:10 */
	aliases {
		gpio-0 = &gpio0;     /* in zephyr/boards/andestech/adp_xc7k_ae350/adp_xc7k_ae350_common.dtsi:11 */
		counter-0 = &pit0;   /* in zephyr/boards/andestech/adp_xc7k_ae350/adp_xc7k_ae350_common.dtsi:12 */
		i2c-0 = &i2c0;       /* in zephyr/boards/andestech/adp_xc7k_ae350/adp_xc7k_ae350_common.dtsi:13 */
		led0 = &seg7_led1_g; /* in zephyr/boards/andestech/adp_xc7k_ae350/adp_xc7k_ae350_common.dtsi:14 */
		led1 = &seg7_led2_g; /* in zephyr/boards/andestech/adp_xc7k_ae350/adp_xc7k_ae350_common.dtsi:15 */
		sw0 = &user_button1; /* in zephyr/boards/andestech/adp_xc7k_ae350/adp_xc7k_ae350_common.dtsi:16 */
		eeprom-0 = &eeprom;  /* in zephyr/boards/andestech/adp_xc7k_ae350/adp_xc7k_ae350_common.dtsi:17 */
	};

	/* node '/chosen' defined in zephyr/boards/andestech/adp_xc7k_ae350/adp_xc7k_ae350_common.dtsi:20 */
	chosen {
		zephyr,console = &uart1;            /* in zephyr/boards/andestech/adp_xc7k_ae350/adp_xc7k_ae350_common.dtsi:21 */
		zephyr,shell-uart = &uart1;         /* in zephyr/boards/andestech/adp_xc7k_ae350/adp_xc7k_ae350_common.dtsi:22 */
		zephyr,sram = &dram;                /* in zephyr/boards/andestech/adp_xc7k_ae350/adp_xc7k_ae350_common.dtsi:23 */
		zephyr,flash = &mx25u16;            /* in zephyr/boards/andestech/adp_xc7k_ae350/adp_xc7k_ae350_common.dtsi:24 */
		zephyr,flash-controller = &mx25u16; /* in zephyr/boards/andestech/adp_xc7k_ae350/adp_xc7k_ae350_common.dtsi:25 */
	};

	/* node '/leds' defined in zephyr/boards/andestech/adp_xc7k_ae350/adp_xc7k_ae350_common.dtsi:28 */
	leds {
		compatible = "gpio-leds"; /* in zephyr/boards/andestech/adp_xc7k_ae350/adp_xc7k_ae350_common.dtsi:29 */

		/* node '/leds/led_1' defined in zephyr/boards/andestech/adp_xc7k_ae350/adp_xc7k_ae350_common.dtsi:31 */
		seg7_led1_a: led_1 {
			label = "7SEG LED1 A";       /* in zephyr/boards/andestech/adp_xc7k_ae350/adp_xc7k_ae350_common.dtsi:32 */
			gpios = < &gpio0 0x10 0x1 >; /* in zephyr/boards/andestech/adp_xc7k_ae350/adp_xc7k_ae350_common.dtsi:33 */
		};

		/* node '/leds/led_2' defined in zephyr/boards/andestech/adp_xc7k_ae350/adp_xc7k_ae350_common.dtsi:36 */
		seg7_led1_b: led_2 {
			label = "7SEG LED1 B";       /* in zephyr/boards/andestech/adp_xc7k_ae350/adp_xc7k_ae350_common.dtsi:37 */
			gpios = < &gpio0 0x11 0x1 >; /* in zephyr/boards/andestech/adp_xc7k_ae350/adp_xc7k_ae350_common.dtsi:38 */
		};

		/* node '/leds/led_3' defined in zephyr/boards/andestech/adp_xc7k_ae350/adp_xc7k_ae350_common.dtsi:41 */
		seg7_led1_c: led_3 {
			label = "7SEG LED1 C";       /* in zephyr/boards/andestech/adp_xc7k_ae350/adp_xc7k_ae350_common.dtsi:42 */
			gpios = < &gpio0 0x12 0x1 >; /* in zephyr/boards/andestech/adp_xc7k_ae350/adp_xc7k_ae350_common.dtsi:43 */
		};

		/* node '/leds/led_4' defined in zephyr/boards/andestech/adp_xc7k_ae350/adp_xc7k_ae350_common.dtsi:46 */
		seg7_led1_d: led_4 {
			label = "7SEG LED1 D";       /* in zephyr/boards/andestech/adp_xc7k_ae350/adp_xc7k_ae350_common.dtsi:47 */
			gpios = < &gpio0 0x13 0x1 >; /* in zephyr/boards/andestech/adp_xc7k_ae350/adp_xc7k_ae350_common.dtsi:48 */
		};

		/* node '/leds/led_5' defined in zephyr/boards/andestech/adp_xc7k_ae350/adp_xc7k_ae350_common.dtsi:51 */
		seg7_led1_e: led_5 {
			label = "7SEG LED1 E";       /* in zephyr/boards/andestech/adp_xc7k_ae350/adp_xc7k_ae350_common.dtsi:52 */
			gpios = < &gpio0 0x14 0x1 >; /* in zephyr/boards/andestech/adp_xc7k_ae350/adp_xc7k_ae350_common.dtsi:53 */
		};

		/* node '/leds/led_6' defined in zephyr/boards/andestech/adp_xc7k_ae350/adp_xc7k_ae350_common.dtsi:56 */
		seg7_led1_f: led_6 {
			label = "7SEG LED1 F";       /* in zephyr/boards/andestech/adp_xc7k_ae350/adp_xc7k_ae350_common.dtsi:57 */
			gpios = < &gpio0 0x15 0x1 >; /* in zephyr/boards/andestech/adp_xc7k_ae350/adp_xc7k_ae350_common.dtsi:58 */
		};

		/* node '/leds/led_7' defined in zephyr/boards/andestech/adp_xc7k_ae350/adp_xc7k_ae350_common.dtsi:61 */
		seg7_led1_g: led_7 {
			label = "7SEG LED1 G";       /* in zephyr/boards/andestech/adp_xc7k_ae350/adp_xc7k_ae350_common.dtsi:62 */
			gpios = < &gpio0 0x16 0x1 >; /* in zephyr/boards/andestech/adp_xc7k_ae350/adp_xc7k_ae350_common.dtsi:63 */
		};

		/* node '/leds/led_8' defined in zephyr/boards/andestech/adp_xc7k_ae350/adp_xc7k_ae350_common.dtsi:66 */
		seg7_led1_dp: led_8 {
			label = "7SEG LED1 DP";      /* in zephyr/boards/andestech/adp_xc7k_ae350/adp_xc7k_ae350_common.dtsi:67 */
			gpios = < &gpio0 0x17 0x1 >; /* in zephyr/boards/andestech/adp_xc7k_ae350/adp_xc7k_ae350_common.dtsi:68 */
		};

		/* node '/leds/led_9' defined in zephyr/boards/andestech/adp_xc7k_ae350/adp_xc7k_ae350_common.dtsi:71 */
		seg7_led2_a: led_9 {
			label = "7SEG LED2 A";       /* in zephyr/boards/andestech/adp_xc7k_ae350/adp_xc7k_ae350_common.dtsi:72 */
			gpios = < &gpio0 0x18 0x1 >; /* in zephyr/boards/andestech/adp_xc7k_ae350/adp_xc7k_ae350_common.dtsi:73 */
		};

		/* node '/leds/led_10' defined in zephyr/boards/andestech/adp_xc7k_ae350/adp_xc7k_ae350_common.dtsi:76 */
		seg7_led2_b: led_10 {
			label = "7SEG LED2 B";       /* in zephyr/boards/andestech/adp_xc7k_ae350/adp_xc7k_ae350_common.dtsi:77 */
			gpios = < &gpio0 0x19 0x1 >; /* in zephyr/boards/andestech/adp_xc7k_ae350/adp_xc7k_ae350_common.dtsi:78 */
		};

		/* node '/leds/led_11' defined in zephyr/boards/andestech/adp_xc7k_ae350/adp_xc7k_ae350_common.dtsi:81 */
		seg7_led2_c: led_11 {
			label = "7SEG LED2 C";       /* in zephyr/boards/andestech/adp_xc7k_ae350/adp_xc7k_ae350_common.dtsi:82 */
			gpios = < &gpio0 0x1a 0x1 >; /* in zephyr/boards/andestech/adp_xc7k_ae350/adp_xc7k_ae350_common.dtsi:83 */
		};

		/* node '/leds/led_12' defined in zephyr/boards/andestech/adp_xc7k_ae350/adp_xc7k_ae350_common.dtsi:86 */
		seg7_led2_d: led_12 {
			label = "7SEG LED2 D";       /* in zephyr/boards/andestech/adp_xc7k_ae350/adp_xc7k_ae350_common.dtsi:87 */
			gpios = < &gpio0 0x1b 0x1 >; /* in zephyr/boards/andestech/adp_xc7k_ae350/adp_xc7k_ae350_common.dtsi:88 */
		};

		/* node '/leds/led_13' defined in zephyr/boards/andestech/adp_xc7k_ae350/adp_xc7k_ae350_common.dtsi:91 */
		seg7_led2_e: led_13 {
			label = "7SEG LED2 E";       /* in zephyr/boards/andestech/adp_xc7k_ae350/adp_xc7k_ae350_common.dtsi:92 */
			gpios = < &gpio0 0x1c 0x1 >; /* in zephyr/boards/andestech/adp_xc7k_ae350/adp_xc7k_ae350_common.dtsi:93 */
		};

		/* node '/leds/led_14' defined in zephyr/boards/andestech/adp_xc7k_ae350/adp_xc7k_ae350_common.dtsi:96 */
		seg7_led2_f: led_14 {
			label = "7SEG LED2 F";       /* in zephyr/boards/andestech/adp_xc7k_ae350/adp_xc7k_ae350_common.dtsi:97 */
			gpios = < &gpio0 0x1d 0x1 >; /* in zephyr/boards/andestech/adp_xc7k_ae350/adp_xc7k_ae350_common.dtsi:98 */
		};

		/* node '/leds/led_15' defined in zephyr/boards/andestech/adp_xc7k_ae350/adp_xc7k_ae350_common.dtsi:101 */
		seg7_led2_g: led_15 {
			label = "7SEG LED2 G";       /* in zephyr/boards/andestech/adp_xc7k_ae350/adp_xc7k_ae350_common.dtsi:102 */
			gpios = < &gpio0 0x1e 0x1 >; /* in zephyr/boards/andestech/adp_xc7k_ae350/adp_xc7k_ae350_common.dtsi:103 */
		};

		/* node '/leds/led_16' defined in zephyr/boards/andestech/adp_xc7k_ae350/adp_xc7k_ae350_common.dtsi:106 */
		seg7_led2_dp: led_16 {
			label = "7SEG LED2 DP";      /* in zephyr/boards/andestech/adp_xc7k_ae350/adp_xc7k_ae350_common.dtsi:107 */
			gpios = < &gpio0 0x1f 0x1 >; /* in zephyr/boards/andestech/adp_xc7k_ae350/adp_xc7k_ae350_common.dtsi:108 */
		};
	};

	/* node '/gpio_keys' defined in zephyr/boards/andestech/adp_xc7k_ae350/adp_xc7k_ae350_common.dtsi:112 */
	gpio_keys {
		compatible = "gpio-keys"; /* in zephyr/boards/andestech/adp_xc7k_ae350/adp_xc7k_ae350_common.dtsi:113 */

		/* node '/gpio_keys/button_1' defined in zephyr/boards/andestech/adp_xc7k_ae350/adp_xc7k_ae350_common.dtsi:115 */
		user_button1: button_1 {
			label = "User SW1";         /* in zephyr/boards/andestech/adp_xc7k_ae350/adp_xc7k_ae350_common.dtsi:116 */
			gpios = < &gpio0 0x0 0x1 >; /* in zephyr/boards/andestech/adp_xc7k_ae350/adp_xc7k_ae350_common.dtsi:117 */
			zephyr,code = < 0xb >;      /* in zephyr/boards/andestech/adp_xc7k_ae350/adp_xc7k_ae350_common.dtsi:118 */
		};

		/* node '/gpio_keys/button_2' defined in zephyr/boards/andestech/adp_xc7k_ae350/adp_xc7k_ae350_common.dtsi:121 */
		user_button2: button_2 {
			label = "User SW2";         /* in zephyr/boards/andestech/adp_xc7k_ae350/adp_xc7k_ae350_common.dtsi:122 */
			gpios = < &gpio0 0x1 0x1 >; /* in zephyr/boards/andestech/adp_xc7k_ae350/adp_xc7k_ae350_common.dtsi:123 */
			zephyr,code = < 0x2 >;      /* in zephyr/boards/andestech/adp_xc7k_ae350/adp_xc7k_ae350_common.dtsi:124 */
		};

		/* node '/gpio_keys/button_3' defined in zephyr/boards/andestech/adp_xc7k_ae350/adp_xc7k_ae350_common.dtsi:127 */
		user_button3: button_3 {
			label = "User SW3";         /* in zephyr/boards/andestech/adp_xc7k_ae350/adp_xc7k_ae350_common.dtsi:128 */
			gpios = < &gpio0 0x2 0x1 >; /* in zephyr/boards/andestech/adp_xc7k_ae350/adp_xc7k_ae350_common.dtsi:129 */
			zephyr,code = < 0x3 >;      /* in zephyr/boards/andestech/adp_xc7k_ae350/adp_xc7k_ae350_common.dtsi:130 */
		};

		/* node '/gpio_keys/button_4' defined in zephyr/boards/andestech/adp_xc7k_ae350/adp_xc7k_ae350_common.dtsi:133 */
		user_button4: button_4 {
			label = "User SW4";         /* in zephyr/boards/andestech/adp_xc7k_ae350/adp_xc7k_ae350_common.dtsi:134 */
			gpios = < &gpio0 0x3 0x1 >; /* in zephyr/boards/andestech/adp_xc7k_ae350/adp_xc7k_ae350_common.dtsi:135 */
			zephyr,code = < 0x4 >;      /* in zephyr/boards/andestech/adp_xc7k_ae350/adp_xc7k_ae350_common.dtsi:136 */
		};

		/* node '/gpio_keys/button_5' defined in zephyr/boards/andestech/adp_xc7k_ae350/adp_xc7k_ae350_common.dtsi:139 */
		user_button5: button_5 {
			label = "User SW5";         /* in zephyr/boards/andestech/adp_xc7k_ae350/adp_xc7k_ae350_common.dtsi:140 */
			gpios = < &gpio0 0x4 0x1 >; /* in zephyr/boards/andestech/adp_xc7k_ae350/adp_xc7k_ae350_common.dtsi:141 */
			zephyr,code = < 0x5 >;      /* in zephyr/boards/andestech/adp_xc7k_ae350/adp_xc7k_ae350_common.dtsi:142 */
		};

		/* node '/gpio_keys/button_6' defined in zephyr/boards/andestech/adp_xc7k_ae350/adp_xc7k_ae350_common.dtsi:145 */
		user_button6: button_6 {
			label = "User SW6";         /* in zephyr/boards/andestech/adp_xc7k_ae350/adp_xc7k_ae350_common.dtsi:146 */
			gpios = < &gpio0 0x5 0x1 >; /* in zephyr/boards/andestech/adp_xc7k_ae350/adp_xc7k_ae350_common.dtsi:147 */
			zephyr,code = < 0x6 >;      /* in zephyr/boards/andestech/adp_xc7k_ae350/adp_xc7k_ae350_common.dtsi:148 */
		};

		/* node '/gpio_keys/button_7' defined in zephyr/boards/andestech/adp_xc7k_ae350/adp_xc7k_ae350_common.dtsi:151 */
		user_button7: button_7 {
			label = "User SW7";         /* in zephyr/boards/andestech/adp_xc7k_ae350/adp_xc7k_ae350_common.dtsi:152 */
			gpios = < &gpio0 0x6 0x1 >; /* in zephyr/boards/andestech/adp_xc7k_ae350/adp_xc7k_ae350_common.dtsi:153 */
			zephyr,code = < 0x7 >;      /* in zephyr/boards/andestech/adp_xc7k_ae350/adp_xc7k_ae350_common.dtsi:154 */
		};
	};
};
